# ESP32S31_RADIO register map
Vendor: Espressif; Series: ESP32-S31; File version: 3.52
Registers are 32-bit, read-write, no defined reset value unless marked. A register's access mark holds for its fields unless they carry their own. Offsets are from the block's base; [hi:lo] are bit positions; 'fields as' and 'values as' point back to an identical list.

## BTDM_RUNTIME_CONTROL — Sparse BTDM low-level runtime and sleep-control window. Complete ESP32-S31 functions prove only the recorded access directions, finite images, low-24-bit publications and four isolated RMW controls. The independently role-mapped runtime-timer start command is named; all other positional names deliberately avoid assigning undocumented peripheral semantics.
Base 0x2010D000
0x00 RUNTIME_TIMER_START_COMMAND wo — Complete current leaf writes finite image 1; an instruction-identical public same-chip predecessor identifies the operation as r_btdm_hal_rtc_start.
  [31:0] COMMAND — Complete command image that starts the BTDM runtime timer.
    on write: 1=START (Start the runtime timer during controller hardware enable.)
0x04 COMMAND_0004 wo — Complete runtime functions write the finite image 1.
  [31:0] IMAGE
0x08 COMMAND_0008 wo — Complete initialization writes the finite image 1.
  [31:0] IMAGE
0x10 COMMAND_0010 wo — Complete runtime functions write the independently observed finite images 2 and 0x00040000.
  [31:0] IMAGE
0x14 COMMAND_0014 wo — Complete runtime functions write the independently observed finite images 0xFFFFFFFF and 0x00040000.
  [31:0] IMAGE
0x1C STATE_001C — One complete runtime function reads the complete word and writes the finite zero image. Inner state encoding remains unknown.
  [31:0] IMAGE
0x20 STATE_0020 — Complete state word read by runtime functions and cleared by two complete paths.
  [31:0] IMAGE
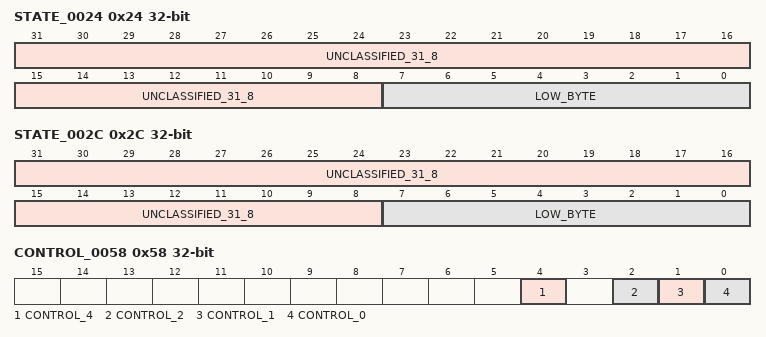
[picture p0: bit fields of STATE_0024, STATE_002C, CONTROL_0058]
0x24 STATE_0024 — State word whose low byte is sampled independently; complete writes publish the finite images zero and one.
  [31:8] UNCLASSIFIED_31_8 — Upper bits covered by complete-register evidence but not assigned a semantic role.
  [7:0] LOW_BYTE
0x2C STATE_002C — State word whose low byte is sampled independently; complete runtime paths clear the word.
  fields as STATE_0024
0x34 COMMAND_0034 wo — Complete initialization writes the finite image 0xFFFFFFFF.
  [31:0] IMAGE
0x38 STATUS_0038 ro — Complete word read by a runtime status path.
  [31:0] IMAGE
0x40 COMMAND_0040 wo — Complete runtime functions write finite images with independently observed bits 0, 16 and 17.
  [31:0] IMAGE
0x44 COMMAND_0044 wo — Complete runtime functions write finite images with independently observed bits 0, 16 and 17.
  [31:0] IMAGE
0x48 STATUS_0048 ro — Complete word read by multiple runtime functions.
  [31:0] IMAGE
0x4C COMMAND_004C wo — Complete initialization writes the finite zero image.
  [31:0] IMAGE
0x58 CONTROL_0058 — Shared runtime control word with independently observed RMW operations over bits 0, 1, 2 and 4. Other bits are preserved.
  [4] CONTROL_4, [2] CONTROL_2 ro, [1] CONTROL_1, [0] CONTROL_0
0x64 VALUE_0064 — One complete runtime function reads the complete word and publishes complete dynamic images. The image remains a register-level fact.
0x68 VALUE_0068 wo — Complete publication replaces bits 0..23 with a runtime-derived value and clears bits 24..31.
  [23:0] VALUE_LOW_24
0x6C VALUE_006C — Complete word is read by one runtime path and receives either a complete runtime-derived image or a runtime-derived low-24-bit image.
  [31:0] IMAGE
0x78 CONTROL_0078 — Initialization sets bit 25 through a fresh-read RMW. Other bits are preserved.
  [25] CONTROL_25

## BLE_HW_POSITIONAL_WORD_1FF0 — Narrow owner for the otherwise unbounded word at 0x20101FF0. Complete ESP32-S31 BLE PHY initialization writes complete image zero followed by complete image one before touching any other radio register. The same ordered writes appear at the same block offset in the named ESP32-C61 counterpart, but neither artifact proves this word's hardware action or membership in the adjacent BTMAC dump range. No wider peripheral extent is claimed.
Base 0x20101FF0
0x00 VALUE wo — Complete ordered images zero then one at BLE PHY register-initialization entry; their hardware meaning remains unknown.
  [31:0] POSITIONAL_IMAGE — Complete positional image; only the ordered zero-then-one publications are proven.
